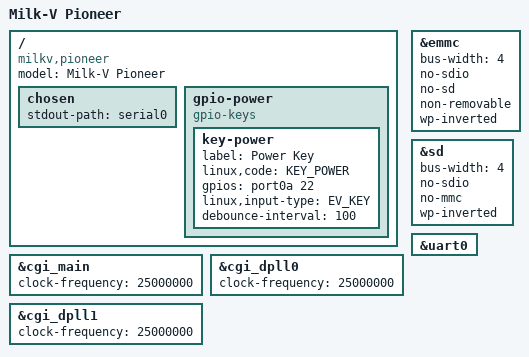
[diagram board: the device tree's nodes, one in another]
// SPDX-License-Identifier: GPL-2.0 OR MIT
/*
 * Copyright (C) 2022 Sophgo Technology Inc. All rights reserved.
 */

#include "sg2042.dtsi"

#include <dt-bindings/gpio/gpio.h>
#include <dt-bindings/input/input.h>

/ {
	model = "Milk-V Pioneer";
	compatible = "milkv,pioneer", "sophgo,sg2042";

	chosen {
		stdout-path = "serial0";
	};

	gpio-power {
		compatible = "gpio-keys";

		key-power {
			label = "Power Key";
			linux,code = <KEY_POWER>;
			gpios = <&port0a 22 GPIO_ACTIVE_HIGH>;
			linux,input-type = <EV_KEY>;
			debounce-interval = <100>;
		};
	};
};

&cgi_main {
	clock-frequency = <25000000>;
};

&cgi_dpll0 {
	clock-frequency = <25000000>;
};

&cgi_dpll1 {
	clock-frequency = <25000000>;
};

&emmc {
	bus-width = <4>;
	no-sdio;
	no-sd;
	non-removable;
	wp-inverted;
	status = "okay";
};

&sd {
	bus-width = <4>;
	no-sdio;
	no-mmc;
	wp-inverted;
	status = "okay";
};

&uart0 {
	status = "okay";
};
